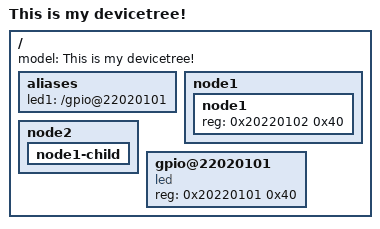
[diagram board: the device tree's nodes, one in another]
/dts-v1/;

/ {
	model = "This is my devicetree!";
	#address-cells = <0x01>;
	#size-cells = <0x01>;

	aliases {
		led1 = "/gpio@22020101";
	};

	node1 {
		#address-cells = <0x01>;
		#size-cells = <0x01>;

		node1 {
			reg = <0x20220102 0x40>;
		};
	};

	node2 {

		node1-child {
		};
	};

	gpio@22020101 {
		compatible = "led";
		reg = <0x20220101 0x40>;
		status = "okay";
	};
};
